# R7KA8P1AD register map
Vendor: Renesas Electronics Corporation; Series: RA8; File version: 1.10.02
CPU: CM85 r0p2, little endian, MPU, FPU, VTOR, 4 interrupt priority bits, 96 interrupts
Registers are 32-bit, read-write, reset 0x0 unless marked. A register's access mark holds for its fields unless they carry their own. Offsets are from the block's base; [hi:lo] are bit positions; {n}, {i} and the like mark numbered series; 'fields as' and 'values as' point back to an identical list.

## ICU — Interrupt Controller
Base 0x4000C000
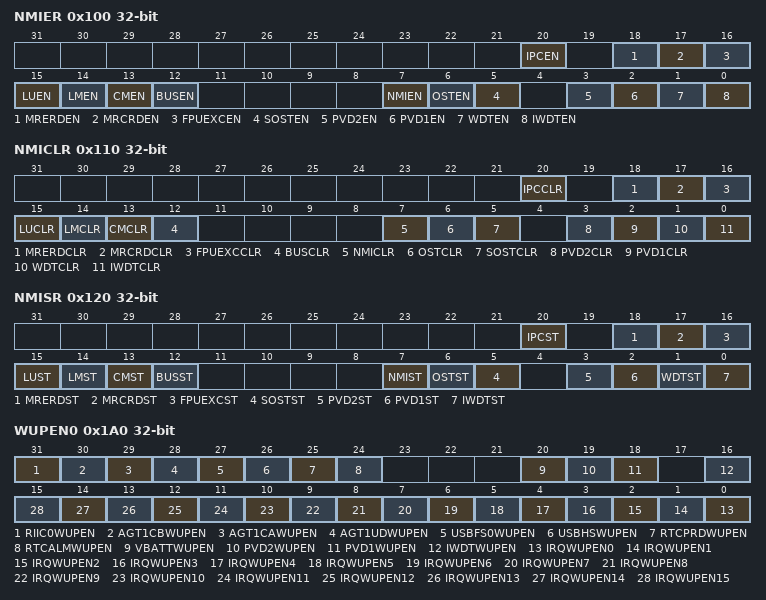
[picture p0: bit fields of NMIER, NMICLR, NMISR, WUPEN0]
0x100 NMIER — Non-Maskable Interrupt Enable Register
  [all] fields
    0=Disabled; 1=Enabled
  [20] IPCEN — IPC NMI CPU mutual Interrupt Enable
  [18] MRERDEN — MRAM MRE read Error Interrupt Enable
  [17] MRCRDEN — MRAM MRC read Error Interrupt Enable
  [16] FPUEXCEN — FPU Exception Interrupt Enable
  [15] LUEN
  [14] LMEN — Local Memory Error Interrupt Enable
  [13] CMEN
  [12] BUSEN
  [7] NMIEN — NMI Pin Interrupt Enable
  [6] OSTEN — Oscillation Stop Detection Interrupt Enable
  [5] SOSTEN — Sub Oscillation Stop Detection Interrupt Enable
  [3] PVD2EN — Voltage monitor 2 Interrupt Enable
  [2] PVD1EN — Voltage monitor 1 Interrupt Enable
  [1] WDTEN — WDT Underflow/Refresh Error Interrupt Enable
  [0] IWDTEN — IWDT Underflow/Refresh Error Interrupt Enable
0x110 NMICLR — Non-Maskable Interrupt Status Clear Register
  [20] IPCCLR — IPC NMI CPU mutual Interrupt Status Flag Clear
    0=No effect; 1=Clear the NMISR.IPCST flag
  [18] MRERDCLR — MRAM MRE read Error Interrupt Status Flag Clear
    0=No effect; 1=Clear the NMISR.MRERDST flag
  [17] MRCRDCLR — MRAM MRC read Error Interrupt Status Flag Clear
    0=No effect; 1=Clear the NMISR.MRCRDST flag
  [16] FPUEXCCLR — FPU Exception Interrupt Status Flag Clear
    0=No effect; 1=Clear the NMISR.FPUEXCST flag
  [15] LUCLR
    0=No effect; 1=Clear the NMISR.LUST flag
  [14] LMCLR
    0=No effect; 1=Clear the NMISR.LMST flag
  [13] CMCLR
    0=No effect; 1=Clear the NMISR.CMST flag
  [12] BUSCLR
    0=No effect; 1=Clear the NMISR.BUSST flag
  [7] NMICLR — NMI Pin Interrupt Status Flag Clear
    0=No effect; 1=Clear the NMISR.NMIST flag
  [6] OSTCLR — Oscillation Stop Detection Interrupt Status Flag Clear
    0=No effect; 1=Clear the NMISR.OSTST flag
  [5] SOSTCLR — Oscillation Stop Detection Interrupt Status Flag Clear
    0=No effect; 1=Clear the NMISR.OSTST flag
  [3] PVD2CLR — Voltage Monitor 2 Interrupt Status Flag Clear
    0=No effect; 1=Clear the NMISR.PVD2ST flag
  [2] PVD1CLR — Voltage Monitor 1 Interrupt Status Flag Clear
    0=No effect; 1=Clear the NMISR.PVD1ST flag
  [1] WDTCLR — WDT Underflow/Refresh Error Interrupt Status Flag Clear
    0=No effect; 1=Clear the NMISR.WDTST flag
  [0] IWDTCLR — IWDT Underflow/Refresh Error Interrupt Status Flag Clear
    0=No effect; 1=Clear the NMISR.IWDTST flag
0x120 NMISR ro — Non-Maskable Interrupt Status Register
  [20] IPCST
    0=Interrupt not requested; 1=Interrupt requested
  [18] MRERDST
    0=Interrupt not requested; 1=Interrupt requested
  [17] MRCRDST
    0=Interrupt not requested; 1=Interrupt requested
  [16] FPUEXCST
    0=Interrupt not requested; 1=Interrupt requested
  [15] LUST
    0=Interrupt not requested; 1=Interrupt requested
  [14] LMST
    0=Interrupt not requested; 1=Interrupt requested
  [13] CMST
    0=Interrupt not requested; 1=Interrupt requested
  [12] BUSST — Bus Error Interrupt Status Flag
    0=Interrupt not requested; 1=Interrupt requested
  [7] NMIST — NMI Pin Interrupt Status Flag
    0=Interrupt not requested; 1=Interrupt requested
  [6] OSTST — Main Clock Oscillation Stop Detection Interrupt Status Flag
    0=Interrupt not requested for main clock oscillation stop; 1=Interrupt requested for main clock oscillation stop
  [5] SOSTST — Sub Oscillation Stop Detection Interrupt Status Flag
    0=Interrupt not requested for sub oscillation stop; 1=Interrupt requested for sub oscillation stop
  [3] PVD2ST — Voltage Monitor 2 Interrupt Status Flag
    0=Interrupt not requested; 1=Interrupt requested
  [2] PVD1ST — Voltage Monitor 1 Interrupt Status Flag
    0=Interrupt not requested; 1=Interrupt requested
  [1] WDTST — WDT Underflow/Refresh Error Interrupt Status Flag
    0=Interrupt not requested; 1=Interrupt requested
  [0] IWDTST — IWDT Underflow/Refresh Error Interrupt Status Flag
    0=Interrupt not requested; 1=Interrupt requested
0x1A0 WUPEN0 — Wake Up Interrupt Enable Register 0
  [31] RIIC0WUPEN — RIIC0 Address Match Interrupt Software Standby Mode Returns Enable bit
    0=Software Standby Mode returns by IIC0 address match A interrupt is disabled; 1=Software Standby Mode returns by IIC0 address match A interrupt is enabled
  [30] AGT1CBWUPEN — AGT1 Compare Match B Interrupt Software Standby Mode Returns Enable bit
    0=Software Standby Mode returns by AGT1 compare match B interrupt is disabled; 1=Software Standby Mode returns by AGT1 compare match B interrupt is enabled
  [29] AGT1CAWUPEN — AGT1 Compare Match A Interrupt Software Standby Mode Returns Enable bit
    0=Software Standby Mode returns by AGT1 compare match A interrupt is disabled; 1=Software Standby Mode returns by AGT1 compare match A interrupt is enabled
  [28] AGT1UDWUPEN — AGT1 Underflow Interrupt Software Standby Mode Returns Enable bit
    0=Software Standby Mode returns by AGT1 underflow interrupt is disabled; 1=Software Standby Mode returns by AGT1 underflow interrupt is enabled
  [27] USBFS0WUPEN — USBFS Interrupt Software Standby Mode Returns Enable bit
    0=Software Standby Mode returns by USBFS interrupt is disabled; 1=Software Standby Mode returns by USBFS interrupt is enabled
  [26] USBHSWUPEN — USBHS Interrupt Software Standby Mode Returns Enable bit
    0=Software Standby Mode returns by USBHS interrupt is disabled; 1=Software Standby Mode returns by USBHS interrupt is enabled
  [25] RTCPRDWUPEN — RTC Period Interrupt Software Standby Mode Returns Enable bit
    0=Software Standby Mode returns by RTC period interrupt is disabled; 1=Software Standby Mode returns by RTC period interrupt is enabled
  [24] RTCALMWUPEN — RTC Alarm Interrupt Software Standby Mode Returns Enable bit
    0=Software Standby Mode returns by RTC alarm interrupt is disabled; 1=Software Standby Mode returns by RTC alarm interrupt is enabled
  [20] VBATTWUPEN — VBATT Monitor Interrupt Software Standby Mode Returns Enable bit
    0=Software Standby Mode returns by VBATT monitor interrupt is disabled; 1=Software Standby Mode returns by VBATT monitor interrupt is enabled
  [19] PVD2WUPEN — PVD2 Interrupt Software Standby Mode Returns Enable bit
    0=Software Standby Mode returns by PVD2 interrupt is disabled; 1=Software Standby Mode returns by PVD2 interrupt is enabled
  [18] PVD1WUPEN — PVD1 Interrupt Software Standby Mode Returns Enable bit
    0=Software Standby Mode returns by PVD1 interrupt is disabled; 1=Software Standby Mode returns by PVD1 interrupt is enabled
  [16] IWDTWUPEN — IWDT Interrupt Software Standby Mode Returns Enable bit
    0=Software Standby Mode returns by IWDT interrupt is disabled; 1=Software Standby Mode returns by IWDT interrupt is enabled
  [n] IRQWUPEN{n} (n=0..15)
    0=Software Standby Mode returns by IRQn interrupt is disabled ; 1=Software Standby Mode returns by IRQn interrupt is enabled
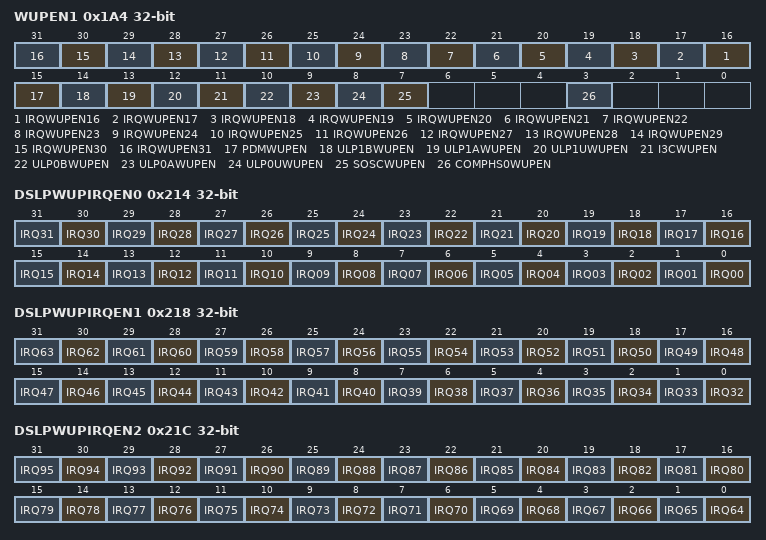
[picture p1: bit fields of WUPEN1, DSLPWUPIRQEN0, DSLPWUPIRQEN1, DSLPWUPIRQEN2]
0x1A4 WUPEN1 — Wake Up Interrupt Enable Register 1
  [n] IRQWUPEN{n} (n=16..31) — Interrupt Software Standby Returns Enable bits IRQ31 to IRQ16
    0=Software Standby returns by IRQn interrupt is disabled; 1=Software Standby returns by IRQn interrupt is enabled
  [15] PDMWUPEN — PDMIF Sound Detection Interrupt Software Standby Returns Enable bit
    0=Software Standby returns by PDMIF Sound Detection interrupt is disabled; 1=Software Standby returns by PDMIF Sound Detection interrupt is enabled
  [14] ULP1BWUPEN — ULPT1 Compare Match B Interrupt Software Standby Mode returns Enable bit
    0=Software Standby returns by ULPT1 Compare match B interrupt is disabled; 1=Software Standby returns by ULPT1 Compare match B interrupt is enabled
  [13] ULP1AWUPEN — ULPT1 Compare Match A Interrupt Software Standby Mode returns Enable bit
    0=Software Standby returns by ULPT1 Compare match A interrupt is disabled; 1=Software Standby returns by ULPT1 Compare match A interrupt is enabled
  [12] ULP1UWUPEN — ULPT1 Underflow Interrupt Software Standby Mode returns Enable bit
    0=Software Standby returns by ULPT1 Underflow interrupt is disabled; 1=Software Standby returns by ULPT1 Underflow interrupt is enabled
  [11] I3CWUPEN — I3C Wakeup Condition Detection Interrupt Software Standby Mode returns Enable bit
    0=Software Standby returns by I3C wake up interrupt is disabled; 1=Software Standby returns by I3C wake up interrupt is enabled
  [10] ULP0BWUPEN — ULPT0 Compare Match B Interrupt Software Standby Mode returns Enable bit
    0=Software Standby returns by ULPT0 Compare match B interrupt is disabled; 1=Software Standby returns by ULPT0 Compare match B interrupt is enabled
  [9] ULP0AWUPEN — ULPT0 Compare Match A Interrupt Software Standby Mode returns Enable bit
    0=Software Standby returns by ULPT0 Compare match A interrupt is disabled; 1=Software Standby returns by ULPT0 Compare match A interrupt is enabled
  [8] ULP0UWUPEN — ULPT0 Underflow Interrupt Software Standby Mode returns Enable bit
    0=Software Standby returns by ULPT0 interrupt is disabled; 1=Software Standby returns by ULPT0 Underflow interrupt is enabled
  [7] SOSCWUPEN — Sub Oscillation Stop Detection Interrupt Software Standby Returns Enable bit
    0=Software Standby returns by Sub Oscillation Stop Detection Interrupt is disabled; 1=Software Standby returns by Sub Oscillation Stop Detection Interrupt is enabled
  [3] COMPHS0WUPEN — Comparator-HS0 Interrupt Software Standby Mode returns Enable bit
    0=Software Standby returns by Comparator-HS0 interrupt is disabled; 1=Software Standby returns by Comparator-HS0 interrupt is enabled
0x214 DSLPWUPIRQEN0 — Deep Sleep Wake Up IRQ Enable Register 0
  [all] fields
    0=Deep Sleep returns by IRQ event is disabled; 1=Deep Sleep returns by IRQ event is enabled
  [n] IRQ{n:02} (n=0..31) — IRQ Deep Sleep Returns Enable bit.
0x218 DSLPWUPIRQEN1 — Deep Sleep Wake Up IRQ Enable Register 1
  [all] fields
    values as the fields of DSLPWUPIRQEN0
  [n-32] IRQ{n} (n=32..63) — IRQ Deep Sleep Returns Enable bit.
0x21C DSLPWUPIRQEN2 — Deep Sleep Wake Up IRQ Enable Register 2
  [all] fields
    values as the fields of DSLPWUPIRQEN0
  [n-64] IRQ{n} (n=64..95) — IRQ Deep Sleep Returns Enable bit.
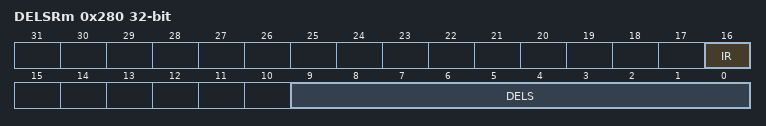
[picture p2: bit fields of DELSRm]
0x280 DELSRm — DMAC Event Link Setting Register m (m = 0 to 7)
  [16] IR — DMAC Activation Request Status flag
    0=No DMAC activation request occurred; 1=DMAC activation request occurred
  [9:0] DELS — DMAC Event Link Select
    0=Disable interrupts to the associated DMAC module; other=Others (Event signal number to be linked. For details, see .)
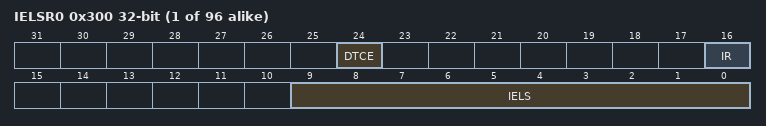
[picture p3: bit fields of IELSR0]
{0x300+4i} IELSR{i} (i=0..95) — Interrupt Controller Unit Event Link Setting Register {i}

## ICU_NS — Interrupt Controller
Base 0x5000C000
Registers as ICU; these are added or differ:
{0x300+4i} IELSR{i} (i=0..95) — Interrupt Controller Unit Event Link Setting Register {i}
  [24] DTCE — DTC Activation Enable
    0=DTC activation is disabled; 1=DTC activation is enabled
  [16] IR — Interrupt Status Flag
    0=No interrupt request generated; 1=An interrupt request is generated
  [9:0] IELS — ICU Event Link Select
    0=Disable interrupts to the associated NVIC or DTC module; other=Others (Event signal number to be linked. For details, see .)
